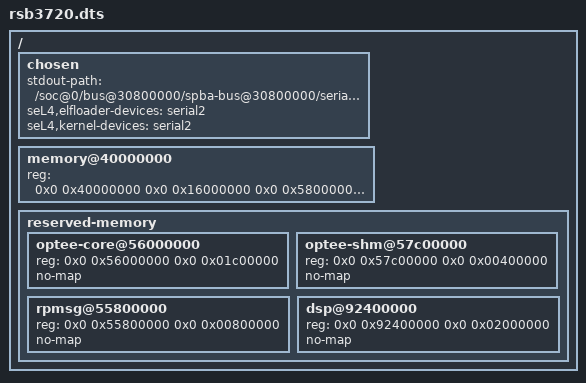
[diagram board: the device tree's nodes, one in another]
/*
 * RSB-3720 i.MX8MP candidate for the pinned upstream imx8mp-evk tree.
 * Match the factory firmware's memory reservations and Linux UART3 console.
 * Build validated only; bootloader console and hardware boot remain untested.
 *
 * The reserved-memory children rely on the base node's #address-cells = <2>,
 * #size-cells = <2> and ranges, which the pinned imx8mp-evk.dts defines. The
 * factory firmware also reserves on-chip RAM at 0x900000; it lies below DRAM,
 * so it is not listed here.
 */
/ {
    chosen {
        stdout-path = "/soc@0/bus@30800000/spba-bus@30800000/serial@30880000";
        seL4,elfloader-devices = "serial2", &{/psci}, &{/timer};
        seL4,kernel-devices = "serial2",
            &{/soc@0/interrupt-controller@38800000}, &{/timer};
    };

    memory@40000000 {
        reg = <0x0 0x40000000 0x0 0x16000000
               0x0 0x58000000 0x0 0xa8000000
               0x1 0x00000000 0x0 0xc0000000>;
    };

    reserved-memory {
        optee-core@56000000 {
            reg = <0x0 0x56000000 0x0 0x01c00000>;
            no-map;
        };
        optee-shm@57c00000 {
            reg = <0x0 0x57c00000 0x0 0x00400000>;
            no-map;
        };
        rpmsg@55800000 {
            reg = <0x0 0x55800000 0x0 0x00800000>;
            no-map;
        };
        dsp@92400000 {
            reg = <0x0 0x92400000 0x0 0x02000000>;
            no-map;
        };
    };
};
